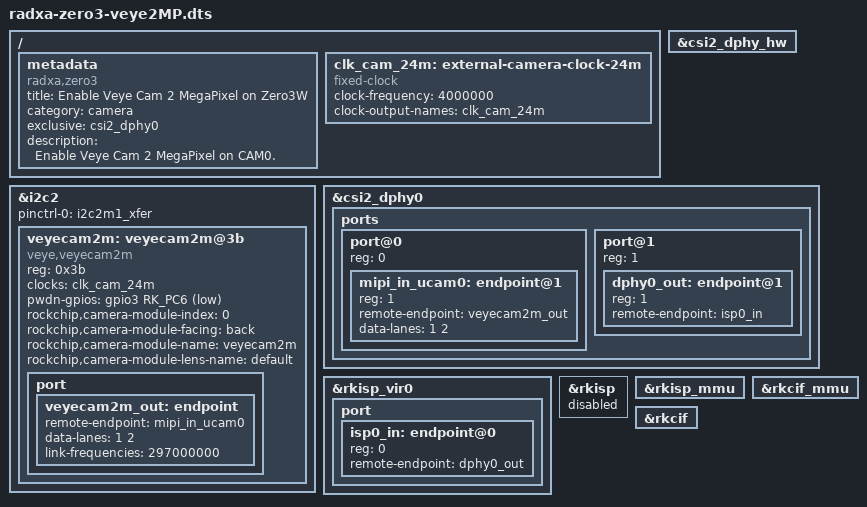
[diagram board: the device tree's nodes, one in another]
/*
 * This file is licensed under the terms of GPLv3.
 * Made by OpenHD
 */

/dts-v1/;
/plugin/;

#include <dt-bindings/power/rk3568-power.h>
#include <dt-bindings/gpio/gpio.h>
#include <dt-bindings/pinctrl/rockchip.h>

/ {
	metadata {
		title = "Enable Veye Cam 2 MegaPixel on Zero3W";
		compatible = "radxa,zero3";
		category = "camera";
		exclusive = "csi2_dphy0";
		description = "Enable Veye Cam 2 MegaPixel on CAM0.";
	};


	fragment@0 {
		target-path = "/";

		__overlay__ {		
			clk_cam_24m: external-camera-clock-24m {
				status = "okay";
				compatible = "fixed-clock";
				clock-frequency = <4000000>;
				clock-output-names = "clk_cam_24m";
				#clock-cells = <0>;
			};


		};
	};

	fragment@1 {
		target = <&i2c2>;


		__overlay__ {
			status = "okay";
			pinctrl-names = "default";
			pinctrl-0 = <&i2c2m1_xfer>;
			#address-cells = <1>;
			#size-cells = <0>;

			veyecam2m: veyecam2m@3b {
				status = "okay";
				compatible = "veye,veyecam2m";
				reg = <0x3b>;
				clocks = <&clk_cam_24m>;
				clock-names = "xvclk";
				pwdn-gpios = <&gpio3 RK_PC6 GPIO_ACTIVE_LOW>;
				rockchip,camera-module-index = <0>;
				rockchip,camera-module-facing = "back";
				rockchip,camera-module-name = "veyecam2m";
				rockchip,camera-module-lens-name = "default";

				port {
					veyecam2m_out: endpoint {
						remote-endpoint = <&mipi_in_ucam0>;
						data-lanes = <1 2>;
						link-frequencies = /bits/ 64 <297000000>;
					};
				};
			};
		};
	};

	fragment@2 {
		target = <&csi2_dphy_hw>;

		__overlay__ {
			status = "okay";
		};
	};

	fragment@3 {
		target = <&csi2_dphy0>;

		__overlay__ {
			status = "okay";

			ports {
				#address-cells = <1>;
				#size-cells = <0>;

				port@0 {
					reg = <0>;
					#address-cells = <1>;
					#size-cells = <0>;

					mipi_in_ucam0: endpoint@1 {
						reg = <1>;
						remote-endpoint = <&veyecam2m_out>;
						data-lanes = <1 2>;
					};
				};

				port@1 {
					reg = <1>;
					#address-cells = <1>;
					#size-cells = <0>;

					dphy0_out: endpoint@1 {
						reg = <1>;
						remote-endpoint = <&isp0_in>;
					};
				};
			};
		};
	};

	fragment@4 {
		target = <&rkisp_vir0>;

		__overlay__ {
			status = "okay";

			port {
				#address-cells = <1>;
				#size-cells = <0>;

				isp0_in: endpoint@0 {
					reg = <0>;
					remote-endpoint = <&dphy0_out>;
				};
			};
		};
	};

	fragment@5 {
		target = <&rkisp>;

		__overlay__ {
			status = "okey";
		};
	};

	fragment@6 {
		target = <&rkisp_mmu>;

		__overlay__ {
			status = "okay";
		};
	};

	fragment@7 {
		target = <&rkcif_mmu>;

		__overlay__ {
			status = "okay";
		};
	};

	fragment@8 {
		target = <&rkcif>;

		__overlay__ {
			status = "okay";
		};
	};
};
